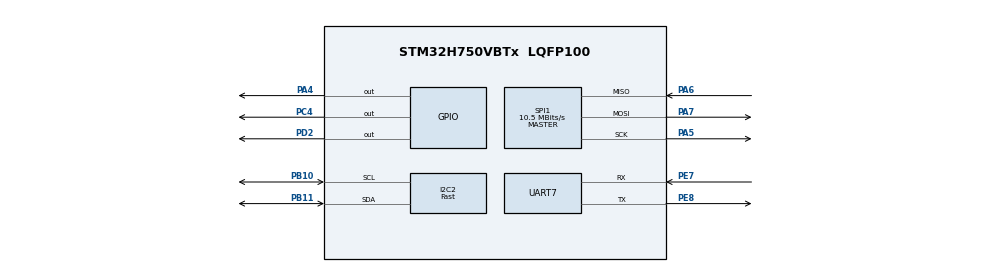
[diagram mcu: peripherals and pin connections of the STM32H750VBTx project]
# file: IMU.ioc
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Dma.Request0=UART7_RX
Dma.Request1=UART7_TX
Dma.Request2=SPI1_RX
Dma.Request3=SPI1_TX
Dma.SPI1_RX.2.Direction=DMA_PERIPH_TO_MEMORY
Dma.SPI1_RX.2.EventEnable=DISABLE
Dma.SPI1_RX.2.FIFOMode=DMA_FIFOMODE_DISABLE
Dma.SPI1_RX.2.Instance=DMA2_Stream4
Dma.SPI1_RX.2.MemDataAlignment=DMA_MDATAALIGN_BYTE
Dma.SPI1_RX.2.MemInc=DMA_MINC_ENABLE
Dma.SPI1_RX.2.Mode=DMA_NORMAL
Dma.SPI1_RX.2.PeriphDataAlignment=DMA_PDATAALIGN_BYTE
Dma.SPI1_RX.2.PeriphInc=DMA_PINC_DISABLE
Dma.SPI1_RX.2.Polarity=HAL_DMAMUX_REQ_GEN_RISING
Dma.SPI1_RX.2.Priority=DMA_PRIORITY_VERY_HIGH
Dma.SPI1_RX.2.RequestNumber=1
Dma.SPI1_RX.2.SignalID=NONE
Dma.SPI1_RX.2.SyncEnable=DISABLE
Dma.SPI1_RX.2.SyncPolarity=HAL_DMAMUX_SYNC_NO_EVENT
Dma.SPI1_RX.2.SyncRequestNumber=1
Dma.SPI1_RX.2.SyncSignalID=NONE
Dma.SPI1_TX.3.Direction=DMA_MEMORY_TO_PERIPH
Dma.SPI1_TX.3.EventEnable=DISABLE
Dma.SPI1_TX.3.FIFOMode=DMA_FIFOMODE_DISABLE
Dma.SPI1_TX.3.Instance=DMA2_Stream5
Dma.SPI1_TX.3.MemDataAlignment=DMA_MDATAALIGN_BYTE
Dma.SPI1_TX.3.MemInc=DMA_MINC_ENABLE
Dma.SPI1_TX.3.Mode=DMA_NORMAL
Dma.SPI1_TX.3.PeriphDataAlignment=DMA_PDATAALIGN_BYTE
Dma.SPI1_TX.3.PeriphInc=DMA_PINC_DISABLE
Dma.SPI1_TX.3.Polarity=HAL_DMAMUX_REQ_GEN_RISING
Dma.SPI1_TX.3.Priority=DMA_PRIORITY_HIGH
Dma.SPI1_TX.3.RequestNumber=1
Dma.SPI1_TX.3.SignalID=NONE
Dma.SPI1_TX.3.SyncEnable=DISABLE
Dma.SPI1_TX.3.SyncPolarity=HAL_DMAMUX_SYNC_NO_EVENT
Dma.SPI1_TX.3.SyncRequestNumber=1
Dma.SPI1_TX.3.SyncSignalID=NONE
Dma.UART7_RX.0.Direction=DMA_PERIPH_TO_MEMORY
Dma.UART7_RX.0.EventEnable=DISABLE
Dma.UART7_RX.0.FIFOMode=DMA_FIFOMODE_DISABLE
Dma.UART7_RX.0.Instance=DMA2_Stream2
Dma.UART7_RX.0.MemDataAlignment=DMA_MDATAALIGN_BYTE
Dma.UART7_RX.0.MemInc=DMA_MINC_ENABLE
Dma.UART7_RX.0.Mode=DMA_NORMAL
Dma.UART7_RX.0.PeriphDataAlignment=DMA_PDATAALIGN_BYTE
Dma.UART7_RX.0.PeriphInc=DMA_PINC_DISABLE
Dma.UART7_RX.0.Polarity=HAL_DMAMUX_REQ_GEN_RISING
Dma.UART7_RX.0.Priority=DMA_PRIORITY_LOW
Dma.UART7_RX.0.RequestNumber=1
Dma.UART7_RX.0.SignalID=NONE
Dma.UART7_RX.0.SyncEnable=DISABLE
Dma.UART7_RX.0.SyncPolarity=HAL_DMAMUX_SYNC_NO_EVENT
Dma.UART7_RX.0.SyncRequestNumber=1
Dma.UART7_RX.0.SyncSignalID=NONE
Dma.UART7_TX.1.Direction=DMA_MEMORY_TO_PERIPH
Dma.UART7_TX.1.EventEnable=DISABLE
Dma.UART7_TX.1.FIFOMode=DMA_FIFOMODE_DISABLE
Dma.UART7_TX.1.Instance=DMA2_Stream3
Dma.UART7_TX.1.MemDataAlignment=DMA_MDATAALIGN_BYTE
Dma.UART7_TX.1.MemInc=DMA_MINC_ENABLE
Dma.UART7_TX.1.Mode=DMA_NORMAL
Dma.UART7_TX.1.PeriphDataAlignment=DMA_PDATAALIGN_BYTE
Dma.UART7_TX.1.PeriphInc=DMA_PINC_DISABLE
Dma.UART7_TX.1.Polarity=HAL_DMAMUX_REQ_GEN_RISING
Dma.UART7_TX.1.Priority=DMA_PRIORITY_LOW
Dma.UART7_TX.1.RequestNumber=1
Dma.UART7_TX.1.SignalID=NONE
Dma.UART7_TX.1.SyncEnable=DISABLE
Dma.UART7_TX.1.SyncPolarity=HAL_DMAMUX_SYNC_NO_EVENT
Dma.UART7_TX.1.SyncRequestNumber=1
Dma.UART7_TX.1.SyncSignalID=NONE
I2C2.I2C_Speed_Mode=I2C_Fast
I2C2.Timing=0x00B03FDB
Mcu.Family=STM32H7
Mcu.Name=STM32H750VBTx
Mcu.Package=LQFP100
NVIC.DMA2_Stream2_IRQn=true\:0\:0\:false\:false\:true\:false\:true\:true
NVIC.DMA2_Stream3_IRQn=true\:0\:0\:false\:false\:true\:false\:true\:true
NVIC.DMA2_Stream4_IRQn=true\:0\:0\:false\:false\:true\:false\:true\:true
NVIC.DMA2_Stream5_IRQn=true\:0\:0\:false\:false\:true\:false\:true\:true
NVIC.I2C2_EV_IRQn=true\:0\:0\:false\:false\:true\:true\:true\:true
NVIC.PriorityGroup=NVIC_PRIORITYGROUP_2
NVIC.SPI1_IRQn=true\:0\:0\:false\:false\:true\:false\:true\:true
NVIC.TIM8_TRG_COM_TIM14_IRQn=true\:0\:0\:true\:false\:true\:true\:true\:true
NVIC.UART7_IRQn=true\:0\:0\:false\:false\:true\:true\:true\:true
PA0.Signal=S_TIM2_CH1_ETR
PA10.Signal=USART1_RX
PA4.GPIO_ModeDefaultOutputPP=GPIO_MODE_OUTPUT_PP
PA4.GPIO_PuPd=GPIO_NOPULL
PA4.PinState=GPIO_PIN_SET
PA4.Signal=GPIO_Output
PA5.GPIO_Speed=GPIO_SPEED_FREQ_VERY_HIGH
PA5.Mode=Full_Duplex_Master
PA5.Signal=SPI1_SCK
PA6.GPIO_PuPd=GPIO_PULLUP
PA6.GPIO_Speed=GPIO_SPEED_FREQ_VERY_HIGH
PA6.Mode=Full_Duplex_Master
PA6.Signal=SPI1_MISO
PA7.GPIO_PuPd=GPIO_PULLUP
PA7.GPIO_Speed=GPIO_SPEED_FREQ_VERY_HIGH
PA7.Mode=Full_Duplex_Master
PA7.Signal=SPI1_MOSI
PA9.Signal=USART1_TX
PB10.GPIO_Pu=GPIO_PULLUP
PB10.Mode=I2C
PB10.Signal=I2C2_SCL
PB11.GPIO_Pu=GPIO_PULLUP
PB11.Mode=I2C
PB11.Signal=I2C2_SDA
PB5.Signal=FDCAN2_RX
PB6.Signal=FDCAN2_TX
PC4.PinState=GPIO_PIN_SET
PC4.Signal=GPIO_Output
PD2.PinState=GPIO_PIN_SET
PD2.Signal=GPIO_Output
PD8.Signal=USART3_TX
PD9.Signal=USART3_RX
PE7.Mode=Asynchronous
PE7.Signal=UART7_RX
PE8.Mode=Asynchronous
PE8.Signal=UART7_TX
PH0-OSC_IN\ (PH0).Mode=HSE-External-Oscillator
PH0-OSC_IN\ (PH0).Signal=RCC_OSC_IN
PH1-OSC_OUT\ (PH1).Mode=HSE-External-Oscillator
PH1-OSC_OUT\ (PH1).Signal=RCC_OSC_OUT
ProjectManager.HeapSize=0x800
ProjectManager.StackSize=0x400
ProjectManager.TargetToolchain=MDK-ARM V5
RCC.ADCFreq_Value=84000000
RCC.APB1Freq_Value=120000000
RCC.APB2Freq_Value=120000000
RCC.APB3Freq_Value=120000000
RCC.APB4Freq_Value=120000000
RCC.CortexFreq_Value=480000000
RCC.D1PPRE=RCC_APB3_DIV2
RCC.D2PPRE1=RCC_APB1_DIV2
RCC.D2PPRE2=RCC_APB2_DIV2
RCC.D3PPRE=RCC_APB4_DIV2
RCC.DIVM1=1
RCC.DIVM2=1
RCC.DIVN1=120
RCC.DIVN2=21
RCC.DIVQ1=24
RCC.HCLKFreq_Value=240000000
RCC.HPRE=RCC_HCLK_DIV2
RCC.HSE_VALUE=8000000
RCC.PLL2FRACN=0
RCC.PLL3FRACN=0
RCC.PLLFRACN=0
RCC.PLLSourceVirtual=RCC_PLLSOURCE_HSE
RCC.SPI123CLockSelection=RCC_SPI123CLKSOURCE_PLL2
RCC.SYSCLKFreq_VALUE=480000000
RCC.SYSCLKSource=RCC_SYSCLKSOURCE_PLLCLK
RCC.USBFreq_Value=40000000
SH.S_TIM2_CH1_ETR.0=TIM2_CH1
SPI1.BaudRatePrescaler=SPI_BAUDRATEPRESCALER_8
SPI1.CalculateBaudRate=10.5 MBits/s
SPI1.DataSize=SPI_DATASIZE_8BIT
SPI1.Direction=SPI_DIRECTION_2LINES
SPI1.Mode=SPI_MODE_MASTER
SPI1.VirtualType=VM_MASTER
TIM14.Period=999
TIM14.Prescaler=239
VP_MEMORYMAP_VS_MEMORYMAP.Mode=CurAppReg
VP_TIM14_VS_ClockSourceINT.Mode=Enable_Timer
board=custom

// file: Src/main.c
/* USER CODE BEGIN Header */
/**
  ******************************************************************************
  * @file           : main.c
  * @brief          : Main program body
  ******************************************************************************
  * @attention
  *
  * <h2><center>&copy; Copyright (c) 2022 STMicroelectronics.
  * All rights reserved.</center></h2>
  *
  * This software component is licensed by ST under BSD 3-Clause license,
  * the "License"; You may not use this file except in compliance with the
  * License. You may obtain a copy of the License at:
  *                        opensource.org/licenses/BSD-3-Clause
  *
  ******************************************************************************
  */
/* USER CODE END Header */
#include "main.h"
#include "dma.h"
#include "i2c.h"
#include "memorymap.h"
#include "spi.h"
#include "tim.h"
#include "usart.h"
#include "gpio.h"

/* USER CODE BEGIN Includes */
//#include "offline_check.h"
#include "hardware_config.h"
#include "mpu6050.h"
/* USER CODE END Includes */

void SystemClock_Config(void);

int main(void)
{

  /* MCU Configuration--------------------------------------------------------*/

  /* Reset of all peripherals, Initializes the Flash interface and the Systick. */
  HAL_Init();

  /* Configure the system clock */
  SystemClock_Config();

  /* Initialize all configured peripherals */
  MX_GPIO_Init();
  MX_DMA_Init();
  MX_I2C2_Init();
  MX_UART7_Init();
  MX_SPI1_Init();
  MX_TIM14_Init();
  /* USER CODE BEGIN 2 */
  HardwareConfig();
  /* USER CODE END 2 */

  /* Infinite loop */
  while (1)
  {

  }
}

void SystemClock_Config(void)
{
  RCC_OscInitTypeDef RCC_OscInitStruct = {0};
  RCC_ClkInitTypeDef RCC_ClkInitStruct = {0};

  /** Supply configuration update enable
  */
  HAL_PWREx_ConfigSupply(PWR_LDO_SUPPLY);

  /** Configure the main internal regulator output voltage
  */
  __HAL_PWR_VOLTAGESCALING_CONFIG(PWR_REGULATOR_VOLTAGE_SCALE1);

  while(!__HAL_PWR_GET_FLAG(PWR_FLAG_VOSRDY)) {}

  __HAL_RCC_SYSCFG_CLK_ENABLE();
  __HAL_PWR_VOLTAGESCALING_CONFIG(PWR_REGULATOR_VOLTAGE_SCALE0);

  while(!__HAL_PWR_GET_FLAG(PWR_FLAG_VOSRDY)) {}

  /** Initializes the RCC Oscillators according to the specified parameters
  * in the RCC_OscInitTypeDef structure.
  */
  RCC_OscInitStruct.OscillatorType = RCC_OSCILLATORTYPE_HSE;
  RCC_OscInitStruct.HSEState = RCC_HSE_ON;
  RCC_OscInitStruct.PLL.PLLState = RCC_PLL_ON;
  RCC_OscInitStruct.PLL.PLLSource = RCC_PLLSOURCE_HSE;
  RCC_OscInitStruct.PLL.PLLM = 1;
  RCC_OscInitStruct.PLL.PLLN = 120;
  RCC_OscInitStruct.PLL.PLLP = 2;
  RCC_OscInitStruct.PLL.PLLQ = 24;
  RCC_OscInitStruct.PLL.PLLR = 2;
  RCC_OscInitStruct.PLL.PLLRGE = RCC_PLL1VCIRANGE_3;
  RCC_OscInitStruct.PLL.PLLVCOSEL = RCC_PLL1VCOWIDE;
  RCC_OscInitStruct.PLL.PLLFRACN = 0;
  if (HAL_RCC_OscConfig(&RCC_OscInitStruct) != HAL_OK)
  {
    Error_Handler();
  }

  /** Initializes the CPU, AHB and APB buses clocks
  */
  RCC_ClkInitStruct.ClockType = RCC_CLOCKTYPE_HCLK|RCC_CLOCKTYPE_SYSCLK
                              |RCC_CLOCKTYPE_PCLK1|RCC_CLOCKTYPE_PCLK2
                              |RCC_CLOCKTYPE_D3PCLK1|RCC_CLOCKTYPE_D1PCLK1;
  RCC_ClkInitStruct.SYSCLKSource = RCC_SYSCLKSOURCE_PLLCLK;
  RCC_ClkInitStruct.SYSCLKDivider = RCC_SYSCLK_DIV1;
  RCC_ClkInitStruct.AHBCLKDivider = RCC_HCLK_DIV2;
  RCC_ClkInitStruct.APB3CLKDivider = RCC_APB3_DIV2;
  RCC_ClkInitStruct.APB1CLKDivider = RCC_APB1_DIV2;
  RCC_ClkInitStruct.APB2CLKDivider = RCC_APB2_DIV2;
  RCC_ClkInitStruct.APB4CLKDivider = RCC_APB4_DIV2;

  if (HAL_RCC_ClockConfig(&RCC_ClkInitStruct, FLASH_LATENCY_4) != HAL_OK)
  {
    Error_Handler();
  }
}

void Error_Handler(void)
{
  __disable_irq();
  while (1)
  {
  }
}
